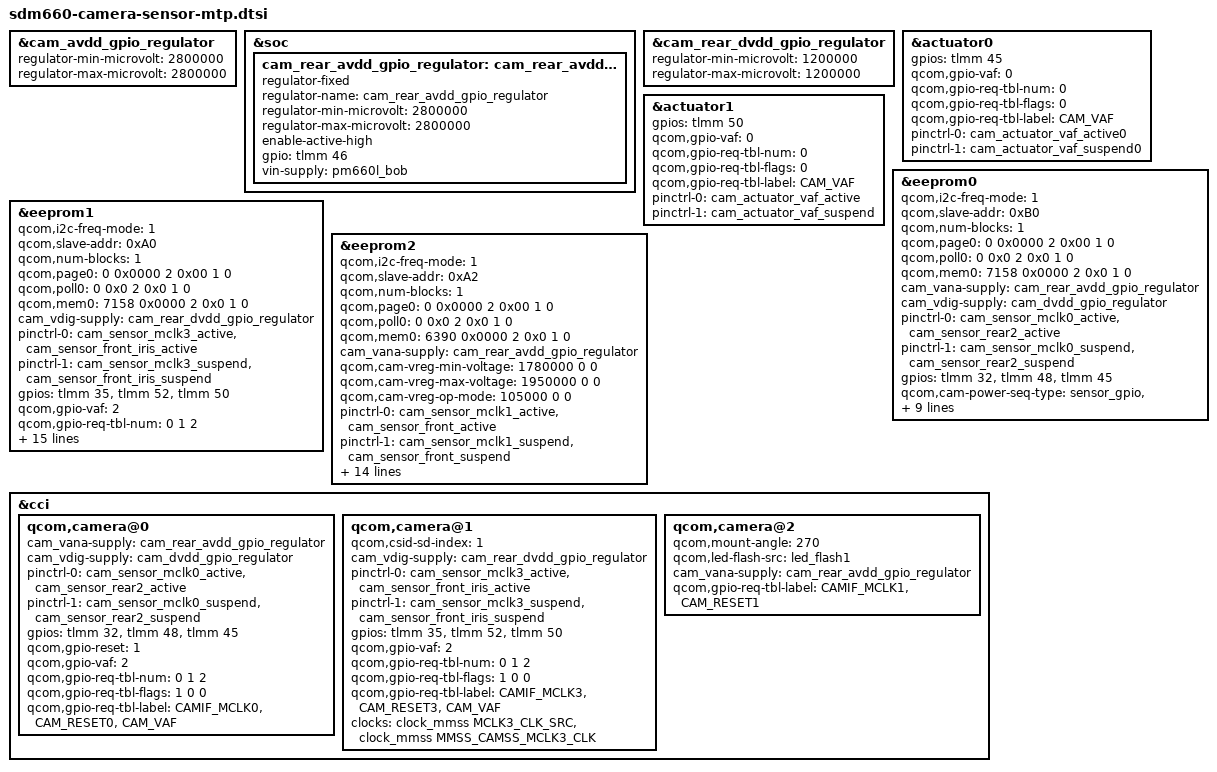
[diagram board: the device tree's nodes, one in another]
&cam_avdd_gpio_regulator {
	regulator-min-microvolt = <2800000>;
	regulator-max-microvolt = <2800000>;
};

/delete-node/ &cam_actuator_regulator;

&soc {
	cam_rear_avdd_gpio_regulator: cam_rear_avdd_fixed_regulator {
		compatible = "regulator-fixed";
		regulator-name = "cam_rear_avdd_gpio_regulator";
		regulator-min-microvolt = <2800000>;
		regulator-max-microvolt = <2800000>;
		enable-active-high;
		gpio = <&tlmm 46 0>;
		vin-supply = <&pm660l_bob>;
	};
};

&cam_rear_dvdd_gpio_regulator {
	regulator-min-microvolt = <1200000>;
	regulator-max-microvolt = <1200000>;
};

&actuator0 {
	/delete-property/ cam_vaf-supply;
	/delete-property/ qcom,cam-vreg-name;
	/delete-property/ qcom,cam-vreg-min-voltage;
	/delete-property/ qcom,cam-vreg-max-voltage;
	/delete-property/ qcom,cam-vreg-op-mode;
	gpios = <&tlmm 45 0>;
	qcom,gpio-vaf = <0>;
	qcom,gpio-req-tbl-num = <0>;
	qcom,gpio-req-tbl-flags = <0>;
	qcom,gpio-req-tbl-label = "CAM_VAF";
	pinctrl-names = "cam_default", "cam_suspend";
	pinctrl-0 = <&cam_actuator_vaf_active0>;
	pinctrl-1 = <&cam_actuator_vaf_suspend0>;
};

&actuator1 {
	/delete-property/ cam_vaf-supply;
	/delete-property/ qcom,cam-vreg-name;
	/delete-property/ qcom,cam-vreg-min-voltage;
	/delete-property/ qcom,cam-vreg-max-voltage;
	/delete-property/ qcom,cam-vreg-op-mode;
	gpios = <&tlmm 50 0>;
	qcom,gpio-vaf = <0>;
	qcom,gpio-req-tbl-num = <0>;
	qcom,gpio-req-tbl-flags = <0>;
	qcom,gpio-req-tbl-label = "CAM_VAF";
	pinctrl-names = "cam_default", "cam_suspend";
	pinctrl-0 = <&cam_actuator_vaf_active>;
	pinctrl-1 = <&cam_actuator_vaf_suspend>;
};

/delete-node/ &actuator2;

/delete-node/ &ois0;

/delete-node/ &tof0;

&eeprom0 {
	qcom,i2c-freq-mode = <1>;
	qcom,slave-addr = <0xB0>;
	qcom,num-blocks = <1>;
	qcom,page0 = <0 0x0000 2 0x00 1 0>;
	qcom,poll0 = <0 0x0 2 0x0 1 0>;
	qcom,mem0 = <7158 0x0000 2 0x0 1 0>;
	cam_vana-supply = <&cam_rear_avdd_gpio_regulator>;
	cam_vdig-supply = <&cam_dvdd_gpio_regulator>;
	pinctrl-0 = <&cam_sensor_mclk0_active
			&cam_sensor_rear2_active>;
	pinctrl-1 = <&cam_sensor_mclk0_suspend
			&cam_sensor_rear2_suspend>;
	gpios = <&tlmm 32 0>,
		<&tlmm 48 0>,
		<&tlmm 45 0>;
	qcom,cam-power-seq-type = "sensor_gpio","sensor_vreg","sensor_vreg","sensor_vreg","sensor_gpio",
		"sensor_clk","sensor_gpio";
	qcom,cam-power-seq-val = "sensor_gpio_reset","cam_vana", "cam_vdig","cam_vio","sensor_gpio_vaf",
		"sensor_cam_mclk","sensor_gpio_reset";
	qcom,cam-power-seq-cfg-val = <0 1 1 1 1 24000000 1>;
	qcom,cam-power-seq-delay =	  <1 1 1 1 1 1 10>;
};

&eeprom1 {
	qcom,i2c-freq-mode = <1>;
	qcom,slave-addr = <0xA0>;
	qcom,num-blocks = <1>;
	qcom,page0 = <0 0x0000 2 0x00 1 0>;
	qcom,poll0 = <0 0x0 2 0x0 1 0>;
	qcom,mem0 = <7158 0x0000 2 0x0 1 0>;
	cam_vdig-supply = <&cam_rear_dvdd_gpio_regulator>;
	pinctrl-0 = <&cam_sensor_mclk3_active
			&cam_sensor_front_iris_active>;
	pinctrl-1 = <&cam_sensor_mclk3_suspend
			&cam_sensor_front_iris_suspend>;
	gpios = <&tlmm 35 0>,
		<&tlmm 52 0>,
		<&tlmm 50 0>;
	qcom,gpio-vaf = <2>;
	qcom,gpio-req-tbl-num = <0 1 2>;
	qcom,gpio-req-tbl-flags = <1 0 0>;
	qcom,gpio-req-tbl-label = "CAMIF_MCLK3","CAM_RESET3","CAM_VAF";
	qcom,cam-power-seq-type = "sensor_gpio","sensor_vreg","sensor_vreg","sensor_vreg","sensor_gpio",
		"sensor_clk","sensor_gpio";
	qcom,cam-power-seq-val = "sensor_gpio_reset","cam_vana","cam_vdig","cam_vio","sensor_gpio_vaf",
		"sensor_cam_mclk","sensor_gpio_reset";
	qcom,cam-power-seq-cfg-val = <0 1 1 1 1 24000000 1>;
	qcom,cam-power-seq-delay = <1 1 1 1 1 1 10>;
	clocks = <&clock_mmss MCLK3_CLK_SRC>,
		<&clock_mmss MMSS_CAMSS_MCLK3_CLK>;
};

&eeprom2 {
	qcom,i2c-freq-mode = <1>;
	qcom,slave-addr = <0xA2>;
	qcom,num-blocks = <1>;
	qcom,page0 = <0 0x0000 2 0x00 1 0>;
	qcom,poll0 = <0 0x0 2 0x0 1 0>;
	qcom,mem0 = <6390 0x0000 2 0x0 1 0>;
	cam_vana-supply = <&cam_rear_avdd_gpio_regulator>;
	qcom,cam-vreg-min-voltage = <1780000 0 0>;
	qcom,cam-vreg-max-voltage = <1950000 0 0>;
	qcom,cam-vreg-op-mode = <105000 0 0>;
	pinctrl-0 = <&cam_sensor_mclk1_active
			&cam_sensor_front_active>;
	pinctrl-1 = <&cam_sensor_mclk1_suspend
			&cam_sensor_front_suspend>;
	gpios = <&tlmm 33 0>,
		<&tlmm 47 0>;
	/delete-property/ qcom,gpio-vana;
	/delete-property/ qcom,gpio-vaf;
	qcom,gpio-req-tbl-num = <0 1>;
	qcom,gpio-req-tbl-flags = <1 0>;
	qcom,gpio-req-tbl-label = "CAMIF_MCLK1","CAM_RESET1";
	qcom,cam-power-seq-type = "sensor_gpio","sensor_vreg","sensor_vreg","sensor_vreg",
		"sensor_clk","sensor_gpio";
	qcom,cam-power-seq-val = "sensor_gpio_reset","cam_vana", "cam_vdig","cam_vio",
		"sensor_cam_mclk","sensor_gpio_reset";
	qcom,cam-power-seq-cfg-val = <0 1 1 1 24000000 1>;
	qcom,cam-power-seq-delay = <1 1 1 1 1 10>;
	qcom,sensor-position = <0>;
};

&cci {
	qcom,camera@0 {
		/delete-property/ qcom,ois-src;
		cam_vana-supply = <&cam_rear_avdd_gpio_regulator>;
		cam_vdig-supply = <&cam_dvdd_gpio_regulator>;
		pinctrl-0 = <&cam_sensor_mclk0_active
				&cam_sensor_rear2_active>;
		pinctrl-1 = <&cam_sensor_mclk0_suspend
				&cam_sensor_rear2_suspend>;
		gpios = <&tlmm 32 0>,
			<&tlmm 48 0>,
			<&tlmm 45 0>;
		qcom,gpio-reset = <1>;
		qcom,gpio-vaf = <2>;
		qcom,gpio-req-tbl-num = <0 1 2>;
		qcom,gpio-req-tbl-flags = <1 0 0>;
		qcom,gpio-req-tbl-label = "CAMIF_MCLK0","CAM_RESET0","CAM_VAF";
	};

	qcom,camera@1 {
		qcom,csid-sd-index = <1>;
		cam_vdig-supply = <&cam_rear_dvdd_gpio_regulator>;
		pinctrl-0 = <&cam_sensor_mclk3_active
				&cam_sensor_front_iris_active>;
		pinctrl-1 = <&cam_sensor_mclk3_suspend
				&cam_sensor_front_iris_suspend>;
		gpios = <&tlmm 35 0>,
			<&tlmm 52 0>,
			<&tlmm 50 0>;
		qcom,gpio-vaf = <2>;
		qcom,gpio-req-tbl-num = <0 1 2>;
		qcom,gpio-req-tbl-flags = <1 0 0>;
		qcom,gpio-req-tbl-label = "CAMIF_MCLK3","CAM_RESET3","CAM_VAF";
		clocks = <&clock_mmss MCLK3_CLK_SRC>,
			<&clock_mmss MMSS_CAMSS_MCLK3_CLK>;
	};

	qcom,camera@2 {
		qcom,mount-angle = <270>;
		qcom,led-flash-src = <&led_flash1>;
		/delete-property/ qcom,actuator-src;
		cam_vana-supply = <&cam_rear_avdd_gpio_regulator>;
		qcom,gpio-req-tbl-label = "CAMIF_MCLK1","CAM_RESET1";
	};

	/delete-node/ qcom,camera@3;
};
